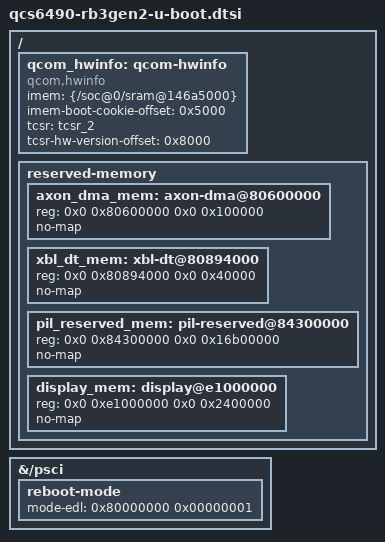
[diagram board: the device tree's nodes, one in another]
// SPDX-License-Identifier: BSD-3-Clause
/*
 * Copyright (c) 2024 Linaro Ltd.
 */
/ {
	/* IMEM boot cookie + TCSR HW version offsets */
	qcom_hwinfo: qcom-hwinfo {
		compatible = "qcom,hwinfo";

		imem = <&{/soc@0/sram@146a5000}>;
		imem-boot-cookie-offset = <0x5000>;

		tcsr = <&tcsr_2>;
		tcsr-hw-version-offset = <0x8000>;
	};

	reserved-memory {
		#address-cells = <2>;
		#size-cells = <2>;
		ranges;

		axon_dma_mem: axon-dma@80600000 {
			reg = <0x0 0x80600000 0x0 0x100000>;
			no-map;
		};

		xbl_dt_mem: xbl-dt@80894000 {
			reg = <0x0 0x80894000 0x0 0x40000>;
			no-map;
		};

		pil_reserved_mem: pil-reserved@84300000 {
			reg = <0x0 0x84300000 0x0 0x16b00000>;
			no-map;
		};

		display_mem: display@e1000000 {
			reg = <0x0 0xe1000000 0x0 0x2400000>;
			no-map;
		};
	};
};

/* Enter Qualcomm EDL/download mode via "reset -edl". */
&{/psci} {
	reboot-mode {
		mode-edl = <0x80000000 0x00000001>;
	};
};
